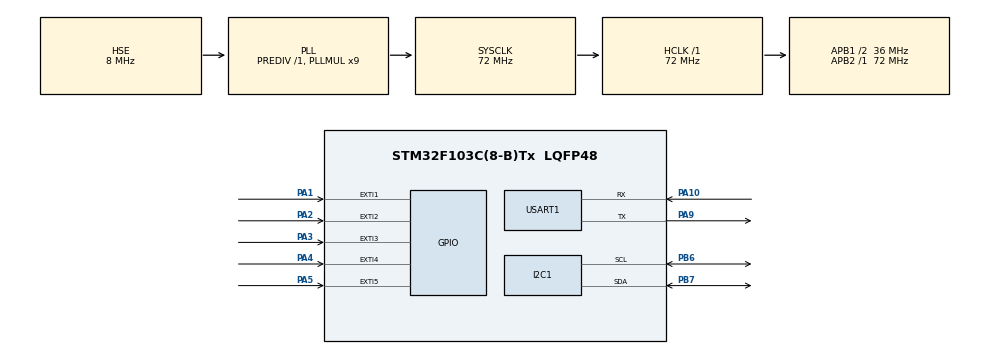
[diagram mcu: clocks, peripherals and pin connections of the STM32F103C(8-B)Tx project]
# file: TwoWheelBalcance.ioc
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Dma.I2C1_RX.0.Direction=DMA_PERIPH_TO_MEMORY
Dma.I2C1_RX.0.Instance=DMA1_Channel7
Dma.I2C1_RX.0.MemDataAlignment=DMA_MDATAALIGN_BYTE
Dma.I2C1_RX.0.MemInc=DMA_MINC_ENABLE
Dma.I2C1_RX.0.Mode=DMA_NORMAL
Dma.I2C1_RX.0.PeriphDataAlignment=DMA_PDATAALIGN_BYTE
Dma.I2C1_RX.0.PeriphInc=DMA_PINC_DISABLE
Dma.I2C1_RX.0.Priority=DMA_PRIORITY_HIGH
Dma.I2C1_TX.1.Direction=DMA_MEMORY_TO_PERIPH
Dma.I2C1_TX.1.Instance=DMA1_Channel6
Dma.I2C1_TX.1.MemDataAlignment=DMA_MDATAALIGN_BYTE
Dma.I2C1_TX.1.MemInc=DMA_MINC_ENABLE
Dma.I2C1_TX.1.Mode=DMA_NORMAL
Dma.I2C1_TX.1.PeriphDataAlignment=DMA_PDATAALIGN_BYTE
Dma.I2C1_TX.1.PeriphInc=DMA_PINC_DISABLE
Dma.I2C1_TX.1.Priority=DMA_PRIORITY_HIGH
Dma.Request0=I2C1_RX
Dma.Request1=I2C1_TX
Dma.Request2=USART1_RX
Dma.Request3=USART1_TX
Dma.USART1_RX.2.Direction=DMA_PERIPH_TO_MEMORY
Dma.USART1_RX.2.Instance=DMA1_Channel5
Dma.USART1_RX.2.MemDataAlignment=DMA_MDATAALIGN_BYTE
Dma.USART1_RX.2.MemInc=DMA_MINC_ENABLE
Dma.USART1_RX.2.Mode=DMA_NORMAL
Dma.USART1_RX.2.PeriphDataAlignment=DMA_PDATAALIGN_BYTE
Dma.USART1_RX.2.PeriphInc=DMA_PINC_DISABLE
Dma.USART1_RX.2.Priority=DMA_PRIORITY_VERY_HIGH
Dma.USART1_TX.3.Direction=DMA_MEMORY_TO_PERIPH
Dma.USART1_TX.3.Instance=DMA1_Channel4
Dma.USART1_TX.3.MemDataAlignment=DMA_MDATAALIGN_BYTE
Dma.USART1_TX.3.MemInc=DMA_MINC_ENABLE
Dma.USART1_TX.3.Mode=DMA_NORMAL
Dma.USART1_TX.3.PeriphDataAlignment=DMA_PDATAALIGN_BYTE
Dma.USART1_TX.3.PeriphInc=DMA_PINC_DISABLE
Dma.USART1_TX.3.Priority=DMA_PRIORITY_HIGH
FREERTOS.Tasks01=defaultTask,-3,128,StartDefaultTask,Default,NULL,Dynamic,NULL,NULL
I2C1.I2C_Mode=I2C_Fast
Mcu.Family=STM32F1
Mcu.Name=STM32F103C(8-B)Tx
Mcu.Package=LQFP48
NVIC.DMA1_Channel4_IRQn=true\:5\:0\:false\:false\:true\:true\:false\:true\:true
NVIC.DMA1_Channel5_IRQn=true\:5\:0\:false\:false\:true\:true\:false\:true\:true
NVIC.DMA1_Channel6_IRQn=true\:5\:0\:false\:false\:true\:true\:false\:true\:true
NVIC.DMA1_Channel7_IRQn=true\:5\:0\:false\:false\:true\:true\:false\:true\:true
NVIC.EXTI1_IRQn=true\:5\:0\:false\:false\:true\:true\:true\:true\:true
NVIC.EXTI2_IRQn=true\:5\:0\:true\:false\:true\:true\:true\:true\:true
NVIC.EXTI3_IRQn=true\:5\:0\:false\:false\:true\:true\:true\:true\:true
NVIC.EXTI4_IRQn=true\:5\:0\:false\:false\:true\:true\:true\:true\:true
NVIC.EXTI9_5_IRQn=true\:5\:0\:false\:false\:true\:true\:true\:true\:true
NVIC.I2C1_EV_IRQn=true\:5\:0\:false\:false\:true\:true\:true\:true\:true
NVIC.PriorityGroup=NVIC_PRIORITYGROUP_4
NVIC.TIM2_IRQn=true\:15\:0\:false\:false\:true\:false\:false\:true\:true
NVIC.TimeBase=TIM2_IRQn
NVIC.TimeBaseIP=TIM2
NVIC.USART1_IRQn=true\:5\:0\:false\:false\:true\:true\:true\:true\:true
PA1.GPIO_ModeDefaultEXTI=GPIO_MODE_IT_RISING_FALLING
PA1.GPIO_PuPd=GPIO_PULLUP
PA1.Signal=GPXTI1
PA10.Mode=Asynchronous
PA10.Signal=USART1_RX
PA13.Mode=Serial_Wire
PA13.Signal=SYS_JTMS-SWDIO
PA14.Mode=Serial_Wire
PA14.Signal=SYS_JTCK-SWCLK
PA2.GPIO_ModeDefaultEXTI=GPIO_MODE_IT_RISING_FALLING
PA2.GPIO_PuPd=GPIO_PULLUP
PA2.Signal=GPXTI2
PA3.GPIO_ModeDefaultEXTI=GPIO_MODE_IT_RISING_FALLING
PA3.GPIO_PuPd=GPIO_PULLUP
PA3.Signal=GPXTI3
PA4.GPIO_ModeDefaultEXTI=GPIO_MODE_IT_RISING_FALLING
PA4.GPIO_PuPd=GPIO_PULLUP
PA4.Signal=GPXTI4
PA5.GPIO_ModeDefaultEXTI=GPIO_MODE_IT_RISING_FALLING
PA5.GPIO_PuPd=GPIO_PULLUP
PA5.Signal=GPXTI5
PA9.Mode=Asynchronous
PA9.Signal=USART1_TX
PB6.GPIO_Mode=GPIO_MODE_AF_OD
PB6.GPIO_Speed=GPIO_SPEED_FREQ_HIGH
PB6.Mode=I2C
PB6.Signal=I2C1_SCL
PB7.GPIO_Speed=GPIO_SPEED_FREQ_HIGH
PB7.Mode=I2C
PB7.Signal=I2C1_SDA
PD0-OSC_IN.Mode=HSE-External-Oscillator
PD0-OSC_IN.Signal=RCC_OSC_IN
PD1-OSC_OUT.Mode=HSE-External-Oscillator
PD1-OSC_OUT.Signal=RCC_OSC_OUT
ProjectManager.HeapSize=0x200
ProjectManager.StackSize=0x400
ProjectManager.TargetToolchain=CMake
RCC.AHBFreq_Value=72000000
RCC.APB1CLKDivider=RCC_HCLK_DIV2
RCC.APB1Freq_Value=36000000
RCC.APB1TimFreq_Value=72000000
RCC.APB2Freq_Value=72000000
RCC.APB2TimFreq_Value=72000000
RCC.HCLKFreq_Value=72000000
RCC.PLLMUL=RCC_PLL_MUL9
RCC.PLLSourceVirtual=RCC_PLLSOURCE_HSE
RCC.SYSCLKFreq_VALUE=72000000
RCC.SYSCLKSource=RCC_SYSCLKSOURCE_PLLCLK
RCC.USBFreq_Value=72000000
USART1.VirtualMode=VM_ASYNC
VP_FREERTOS_VS_CMSIS_V1.Mode=CMSIS_V1
VP_SYS_VS_tim2.Mode=TIM2
board=custom

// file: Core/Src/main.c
/* USER CODE BEGIN Header */
/**
  ******************************************************************************
  * @file           : main.c
  * @brief          : Main program body
  ******************************************************************************
  * @attention
  *
  * Copyright (c) 2026 STMicroelectronics.
  * All rights reserved.
  *
  * This software is licensed under terms that can be found in the LICENSE file
  * in the root directory of this software component.
  * If no LICENSE file comes with this software, it is provided AS-IS.
  *
  ******************************************************************************
  */
/* USER CODE END Header */
#include "main.h"
#include "cmsis_os.h"
#include "dma.h"
#include "i2c.h"
#include "usart.h"
#include "gpio.h"

/* USER CODE BEGIN Includes */
#include "MPU6050.h"
#include "debug_vars.h"
#include "bsp_dwt.h"
#include "tcrt.h"
/* USER CODE END Includes */

void SystemClock_Config(void);
void MX_FREERTOS_Init(void);

/* USER CODE BEGIN 0 */
// // 注意：请将此回调放在 stm32f1xx_it.c 或统一的中断处理文件中，且只保留一份！
// void HAL_GPIO_EXTI_Callback(uint16_t GPIO_Pin) {
//   tcrt_instance.handleInterrupt(GPIO_Pin);
//   // 如有其他引脚中断，可在此添加 else if 分支
// }
/* USER CODE END 0 */

int main(void)
{

  /* MCU Configuration--------------------------------------------------------*/

  /* Reset of all peripherals, Initializes the Flash interface and the Systick. */
  HAL_Init();

  /* Configure the system clock */
  SystemClock_Config();

  /* USER CODE BEGIN SysInit */
 BSP_DWT_Init();
  /* USER CODE END SysInit */

  /* Initialize all configured peripherals */
  MX_GPIO_Init();
  MX_DMA_Init();
  MX_I2C1_Init();
  MX_USART1_UART_Init();
  /* USER CODE BEGIN 2 */
  //MPU6050_Init();

  /* USER CODE END 2 */

  /* Call init function for freertos objects (in cmsis_os2.c) */
  MX_FREERTOS_Init();

  /* Start scheduler */
  osKernelStart();

  /* We should never get here as control is now taken by the scheduler */

  /* Infinite loop */
  while (1)
  {

  }
}

void SystemClock_Config(void)
{
  RCC_OscInitTypeDef RCC_OscInitStruct = {0};
  RCC_ClkInitTypeDef RCC_ClkInitStruct = {0};

  /** Initializes the RCC Oscillators according to the specified parameters
  * in the RCC_OscInitTypeDef structure.
  */
  RCC_OscInitStruct.OscillatorType = RCC_OSCILLATORTYPE_HSE;
  RCC_OscInitStruct.HSEState = RCC_HSE_ON;
  RCC_OscInitStruct.HSEPredivValue = RCC_HSE_PREDIV_DIV1;
  RCC_OscInitStruct.HSIState = RCC_HSI_ON;
  RCC_OscInitStruct.PLL.PLLState = RCC_PLL_ON;
  RCC_OscInitStruct.PLL.PLLSource = RCC_PLLSOURCE_HSE;
  RCC_OscInitStruct.PLL.PLLMUL = RCC_PLL_MUL9;
  if (HAL_RCC_OscConfig(&RCC_OscInitStruct) != HAL_OK)
  {
    Error_Handler();
  }

  /** Initializes the CPU, AHB and APB buses clocks
  */
  RCC_ClkInitStruct.ClockType = RCC_CLOCKTYPE_HCLK|RCC_CLOCKTYPE_SYSCLK
                              |RCC_CLOCKTYPE_PCLK1|RCC_CLOCKTYPE_PCLK2;
  RCC_ClkInitStruct.SYSCLKSource = RCC_SYSCLKSOURCE_PLLCLK;
  RCC_ClkInitStruct.AHBCLKDivider = RCC_SYSCLK_DIV1;
  RCC_ClkInitStruct.APB1CLKDivider = RCC_HCLK_DIV2;
  RCC_ClkInitStruct.APB2CLKDivider = RCC_HCLK_DIV1;

  if (HAL_RCC_ClockConfig(&RCC_ClkInitStruct, FLASH_LATENCY_2) != HAL_OK)
  {
    Error_Handler();
  }
}

void HAL_TIM_PeriodElapsedCallback(TIM_HandleTypeDef *htim)
{
  if (htim->Instance == TIM2)
  {
    HAL_IncTick();
  }
}

void Error_Handler(void)
{
  __disable_irq();
  while (1)
  {
  }
}

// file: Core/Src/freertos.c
/* USER CODE BEGIN Header */
/**
  ******************************************************************************
  * File Name          : freertos.c
  * Description        : Code for freertos applications
  ******************************************************************************
  * @attention
  *
  * Copyright (c) 2026 STMicroelectronics.
  * All rights reserved.
  *
  * This software is licensed under terms that can be found in the LICENSE file
  * in the root directory of this software component.
  * If no LICENSE file comes with this software, it is provided AS-IS.
  *
  ******************************************************************************
  */
/* USER CODE END Header */

#include "FreeRTOS.h"
#include "task.h"
#include "main.h"
#include "cmsis_os.h"

/* USER CODE BEGIN Includes */
void MPU6050ReadTask_Init();
void TrakTask_Init(void);
/* USER CODE END Includes */

osThreadId defaultTaskHandle;

void StartDefaultTask(void const * argument);

void MX_FREERTOS_Init(void); /* (MISRA C 2004 rule 8.1) */

/* GetIdleTaskMemory prototype (linked to static allocation support) */
void vApplicationGetIdleTaskMemory( StaticTask_t **ppxIdleTaskTCBBuffer, StackType_t **ppxIdleTaskStackBuffer, uint32_t *pulIdleTaskStackSize );

/* USER CODE BEGIN GET_IDLE_TASK_MEMORY */
static StaticTask_t xIdleTaskTCBBuffer;
static StackType_t xIdleStack[configMINIMAL_STACK_SIZE];

void vApplicationGetIdleTaskMemory( StaticTask_t **ppxIdleTaskTCBBuffer, StackType_t **ppxIdleTaskStackBuffer, uint32_t *pulIdleTaskStackSize )
{
  *ppxIdleTaskTCBBuffer = &xIdleTaskTCBBuffer;
  *ppxIdleTaskStackBuffer = &xIdleStack[0];
  *pulIdleTaskStackSize = configMINIMAL_STACK_SIZE;
  /* place for user code */
}
/* USER CODE END GET_IDLE_TASK_MEMORY */

void MX_FREERTOS_Init(void) {

  /* Create the thread(s) */
  /* definition and creation of defaultTask */
  osThreadDef(defaultTask, StartDefaultTask, osPriorityIdle, 0, 128);
  defaultTaskHandle = osThreadCreate(osThread(defaultTask), NULL);

  /* USER CODE BEGIN RTOS_THREADS */
  /* add threads, ... */
   MPU6050ReadTask_Init();
  TrakTask_Init();
  /* USER CODE END RTOS_THREADS */

}

void StartDefaultTask(void const * argument)
{
  for(;;)
  {
    osDelay(1);
  }
}
